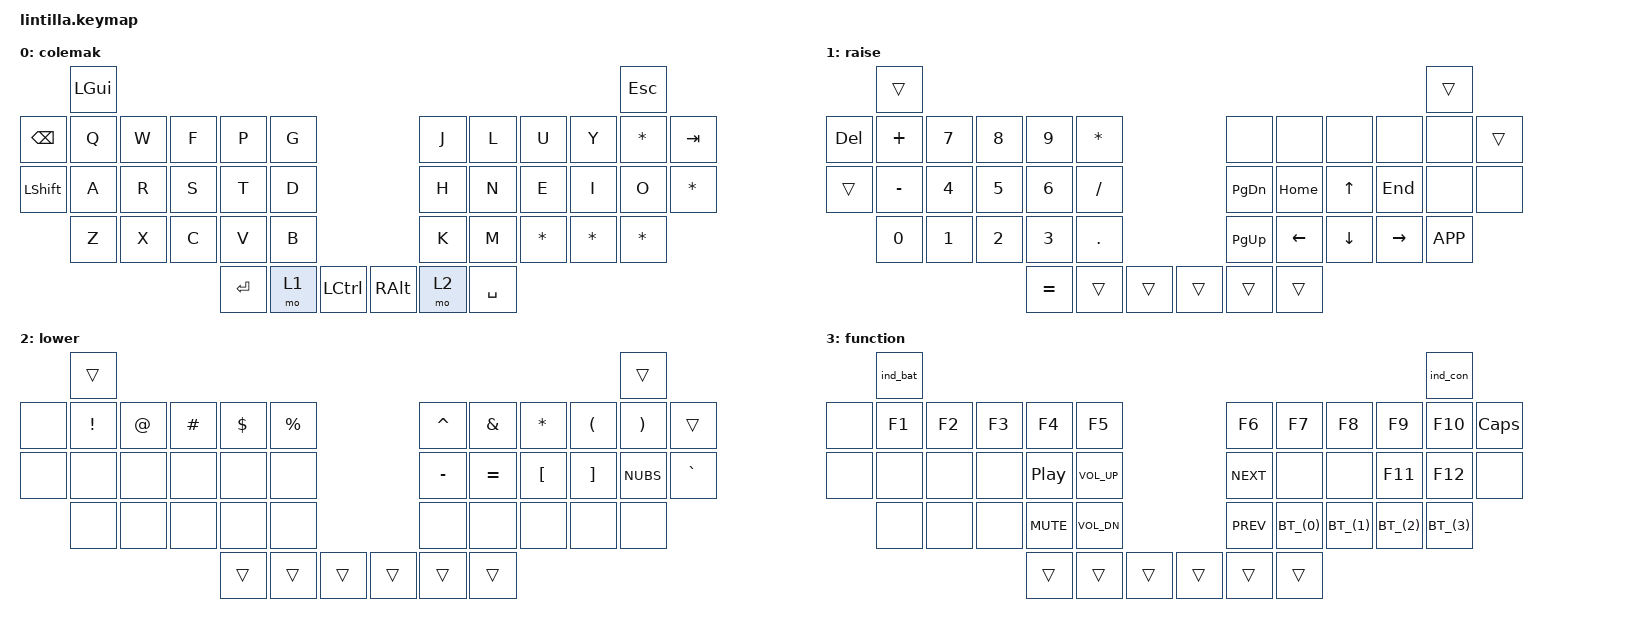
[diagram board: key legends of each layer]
#include <behaviors.dtsi>
#include <dt-bindings/zmk/bt.h>
#include <dt-bindings/zmk/keys.h>
#include <dt-bindings/zmk/outputs.h>
#include <behaviors/rgbled_widget.dtsi>


    keymap {
        compatible = "zmk,keymap";

        qwerty {
//                       ┏━━━━━━━━━━━━━━━━━━━━━━━━━┓
            display-name = "colemak"                ;
//                       ┗━━━━━━━━━━━━━━━━━━━━━━━━━┛
            bindings = <
//         ┏━━━━━━━┓                                                                                          ┏━━━━━━━┓
//         ┃  WIN  ┃                                                                                          ┃  ESC  ┃
            &kp LGUI                                                                                           &kp ESC
//         ┃       ┃                                                                                          ┃       ┃
// ┏━━━━━━━╋━━━━━━━╋━━━━━━━┳━━━━━━━┳━━━━━━━┳━━━━━━━┓                          ┏━━━━━━━┳━━━━━━━┳━━━━━━━┳━━━━━━━╋━━━━━━━╋━━━━━━━┓
// ┃  BSPC ┃   Q   ┃   W   ┃   F   ┃   P   ┃   G   ┃                          ┃   J   ┃   L   ┃   U   ┃   Y   ┃   :   ┃  TAB  ┃
   &kp BSPC  &kp Q   &kp W   &kp F   &kp P   &kp G                              &kp J   &kp L   &kp U   &kp Y  &kp STAR &kp TAB
// ┣━━━━━━━╋━━━━━━━╋━━━━━━━╋━━━━━━━╋━━━━━━━╋━━━━━━━┫                          ┣━━━━━━━╋━━━━━━━╋━━━━━━━╋━━━━━━━╋━━━━━━━╋━━━━━━━┫
// ┃ SHIFT ┃   A   ┃   R   ┃   S   ┃   T   ┃   D   ┃                          ┃   H   ┃   N   ┃   E   ┃   I   ┃   O   ┃   '   ┃
  &kp LSHFT  &kp A   &kp R   &kp S   &kp T   &kp D                              &kp H   &kp N   &kp E   &kp I  &kp O   &kp STAR
// ┃       ┃       ┃       ┃       ┃       ┃       ┃                          ┃       ┃       ┃       ┃       ┃       ┃       ┃
// ┗━━━━━━━╋━━━━━━━╋━━━━━━━╋━━━━━━━╋━━━━━━━╋━━━━━━━┫                          ┣━━━━━━━╋━━━━━━━╋━━━━━━━╋━━━━━━━╋━━━━━━━╋━━━━━━━┛
//         ┃   Z   ┃   X   ┃   C   ┃   V   ┃   B   ┃                          ┃   K   ┃   M   ┃   ,   ┃   .   ┃  / \  ┃
             &kp Z   &kp X   &kp C   &kp V   &kp B                              &kp K   &kp M &kp STAR &kp STAR &kp STAR
//         ┗━━━━━━━┻━━━━━━━┻━━━━━━━┻━━━┳━━━┻━━━┳━━━┻━━━┳━━━━━━━┓  ┏━━━━━━━┳━━━┻━━━┳━━━┻━━━┳━━━┻━━━━━━━┻━━━━━━━┻━━━━━━━┛
//                                     ┃ RET   ┃ RAISE ┃ L CTL ┃  ┃ RALT  ┃ LOWER ┃ SPACE ┃
                                        &kp RET  &mo 1  &kp LCTL   &kp RALT &mo  2 &kp SPACE
//                                     ┗━━━━━━━┫       ┣━━━━━━━┛  ┗━━━━━━━┫       ┣━━━━━━━┛
//                                             ┗━━━━━━━┛                  ┗━━━━━━━┛
            >;
        };

        num {
//                       ┏━━━━━━━━━━━━━━━━━━━━━━━━━┓
            display-name = "raise"                ;
//                       ┗━━━━━━━━━━━━━━━━━━━━━━━━━┛
            bindings = <
//         ┏━━━━━━━┓                                                                                          ┏━━━━━━━┓
//         ┃       ┃                                                                                          ┃       ┃
             &trans                                                                                             &trans
// ┏━━━━━━━╋━━━━━━━╋━━━━━━━┳━━━━━━━┳━━━━━━━┳━━━━━━━┓                          ┏━━━━━━━┳━━━━━━━┳━━━━━━━┳━━━━━━━╋━━━━━━━╋━━━━━━━┓
// ┃  DEL  ┃   +   ┃   7   ┃   8   ┃   9   ┃   *   ┃                          ┃       ┃       ┃       ┃       ┃       ┃       ┃
   &kp DEL &kp PLUS &kp N7 &kp N8  &kp N9 &kp STAR                              &none   &none   &none   &none   &none   &trans
// ┣━━━━━━━╋━━━━━━━╋━━━━━━━╋━━━━━━━╋━━━━━━━╋━━━━━━━┫                          ┣━━━━━━━╋━━━━━━━╋━━━━━━━╋━━━━━━━╋━━━━━━━╋━━━━━━━┫
// ┃       ┃   -   ┃   4   ┃   5   ┃   6   ┃   /   ┃                          ┃  PGUP ┃ HOME  ┃   UP  ┃ END   ┃       ┃       ┃
    &trans &kp MINUS &kp N4  &kp N5  &kp N6 &kp FSLH                         &kp PG_DN &kp HOME &kp UP &kp END  &none   &none
// ┃       ┃       ┃       ┃       ┃       ┃       ┃                          ┃       ┃       ┃       ┃       ┃       ┃       ┃
// ┗━━━━━━━╋━━━━━━━╋━━━━━━━╋━━━━━━━╋━━━━━━━╋━━━━━━━┫                          ┣━━━━━━━╋━━━━━━━╋━━━━━━━╋━━━━━━━╋━━━━━━━╋━━━━━━━┛
//         ┃   0   ┃   1   ┃   2   ┃   3   ┃   .   ┃                          ┃  PGDN ┃  LEFT ┃  DOWN ┃ RIGHT ┃ RAPP  ┃
            &kp N0  &kp N1   &kp N2  &kp N3 &kp DOT                          &kp PG_UP &kp LEFT &kp DOWN &kp RIGHT &kp K_APP
//         ┗━━━━━━━┻━━━━━━━┻━━━━━━━┻━━━┳━━━┻━━━┳━━━┻━━━┳━━━━━━━┓  ┏━━━━━━━┳━━━┻━━━┳━━━┻━━━┳━━━┻━━━━━━━┻━━━━━━━┻━━━━━━━┛
//                                     ┃   =   ┃       ┃       ┃  ┃       ┃       ┃       ┃
                                       &kp EQUAL &trans  &trans     &trans  &trans  &trans
//                                     ┗━━━━━━━┫       ┣━━━━━━━┛  ┗━━━━━━━┫       ┣━━━━━━━┛
//                                             ┗━━━━━━━┛                  ┗━━━━━━━┛
            >;
        };

        nav {
//                       ┏━━━━━━━━━━━━━━━━━━━━━━━━━┓
            display-name = "lower"                 ;
//                       ┗━━━━━━━━━━━━━━━━━━━━━━━━━┛
            bindings = <
//         ┏━━━━━━━┓                                                                                          ┏━━━━━━━┓
//         ┃       ┃                                                                                          ┃       ┃
             &trans                                                                                            &trans
// ┏━━━━━━━╋━━━━━━━╋━━━━━━━┳━━━━━━━┳━━━━━━━┳━━━━━━━┓                          ┏━━━━━━━┳━━━━━━━┳━━━━━━━┳━━━━━━━╋━━━━━━━╋━━━━━━━┓
// ┃       ┃   !   ┃   @   ┃   #   ┃   $   ┃   %   ┃                          ┃   ^   ┃   &   ┃   *   ┃   (   ┃   )   ┃       ┃
     &none  &kp EXCL &kp AT &kp HASH &kp DLLR &kp PRCNT                        &kp CARET &kp AMPS &kp STAR &kp LPAR &kp RPAR &trans
// ┣━━━━━━━╋━━━━━━━╋━━━━━━━╋━━━━━━━╋━━━━━━━╋━━━━━━━┫                          ┣━━━━━━━╋━━━━━━━╋━━━━━━━╋━━━━━━━╋━━━━━━━╋━━━━━━━┫
// ┃       ┃       ┃       ┃       ┃       ┃       ┃                          ┃  - _  ┃  + =  ┃ [ {   ┃  ] }  ┃  \ |  ┃  ` ~  ┃
     &none   &none   &none   &none   &none   &none                          &kp MINUS &kp EQUAL &kp LBKT &kp RBKT &kp NUBS &kp GRAVE
// ┃       ┃       ┃       ┃       ┃       ┃       ┃                          ┃       ┃       ┃       ┃       ┃       ┃       ┃
// ┗━━━━━━━╋━━━━━━━╋━━━━━━━╋━━━━━━━╋━━━━━━━╋━━━━━━━┫                          ┣━━━━━━━╋━━━━━━━╋━━━━━━━╋━━━━━━━╋━━━━━━━╋━━━━━━━┛
//         ┃       ┃       ┃       ┃       ┃       ┃                          ┃       ┃       ┃       ┃       ┃       ┃
             &none   &none   &none   &none   &none                              &none   &none   &none   &none   &none
//         ┗━━━━━━━┻━━━━━━━┻━━━━━━━┻━━━┳━━━┻━━━┳━━━┻━━━┳━━━━━━━┓  ┏━━━━━━━┳━━━┻━━━┳━━━┻━━━┳━━━┻━━━━━━━┻━━━━━━━┻━━━━━━━┛
//                                     ┃       ┃       ┃       ┃  ┃       ┃       ┃       ┃
                                         &trans  &trans  &trans     &trans  &trans  &trans
//                                     ┗━━━━━━━┫       ┣━━━━━━━┛  ┗━━━━━━━┫       ┣━━━━━━━┛
//                                             ┗━━━━━━━┛                  ┗━━━━━━━┛
            >;
        };

        fn {
//                       ┏━━━━━━━━━━━━━━━━━━━━━━━━━┓
            display-name = "function"              ;
//                       ┗━━━━━━━━━━━━━━━━━━━━━━━━━┛
            bindings = <
//         ┏━━━━━━━┓                                                                                          ┏━━━━━━━┓
//         ┃Battery┃                                                                                          ┃CON LED┃
            &ind_bat                                                                                           &ind_con
// ┏━━━━━━━╋━━━━━━━╋━━━━━━━┳━━━━━━━┳━━━━━━━┳━━━━━━━┓                          ┏━━━━━━━┳━━━━━━━┳━━━━━━━┳━━━━━━━╋━━━━━━━╋━━━━━━━┓
// ┃       ┃  F1   ┃  F2   ┃  F3   ┃   F4  ┃  F5   ┃                          ┃  F6   ┃   F7  ┃  F8   ┃  F9   ┃  F10  ┃ CPSLK ┃
     &none   &kp F1 &kp F2  &kp F3  &kp F4   &kp F5                            &kp F6  &kp F7  &kp F8  &kp F9  &kp F10 &kp CAPS
// ┣━━━━━━━╋━━━━━━━╋━━━━━━━╋━━━━━━━╋━━━━━━━╋━━━━━━━┫                          ┣━━━━━━━╋━━━━━━━╋━━━━━━━╋━━━━━━━╋━━━━━━━╋━━━━━━━┫
// ┃SCRNSHT┃       ┃       ┃       ┃  PLAY ┃  VOL+ ┃                          ┃  NEXT ┃       ┃       ┃  F11  ┃  F12  ┃TSKMNGR┃
     &none   &none  &none   &none &kp C_PP &kp C_VOL_UP                      &kp C_NEXT &none   &none  &kp F11 &kp F12  &none
// ┗━━━━━━━╋━━━━━━━╋━━━━━━━╋━━━━━━━╋━━━━━━━╋━━━━━━━┫                          ┣━━━━━━━╋━━━━━━━╋━━━━━━━╋━━━━━━━╋━━━━━━━╋━━━━━━━┛
//         ┃       ┃       ┃       ┃  MUTE ┃  VOL- ┃                          ┃  PRVS ┃  BT1  ┃  BT2  ┃  BT3  ┃  BT4  ┃
            &none   &none   &none &kp C_MUTE &kp C_VOL_DN                     &kp C_PREV BT_(0)  BT_(1)  BT_(2)  BT_(3)
//         ┗━━━━━━━┻━━━━━━━┻━━━━━━━┻━━━┳━━━┻━━━┳━━━┻━━━┳━━━━━━━┓  ┏━━━━━━━┳━━━┻━━━┳━━━┻━━━┳━━━┻━━━━━━━┻━━━━━━━┻━━━━━━━┛
//                                     ┃       ┃       ┃       ┃  ┃       ┃       ┃       ┃
                                         &trans  &trans  &trans    &trans  &trans   &trans
//                                     ┗━━━━━━━┫       ┣━━━━━━━┛  ┗━━━━━━━┫       ┣━━━━━━━┛
//                                             ┗━━━━━━━┛                  ┗━━━━━━━┛
            >;
        };

  
        // Extra empty layers for ZMK Studio
    };
};

// vim: expandtab softtabstop=4 shiftwidth=4 filetype=dts
